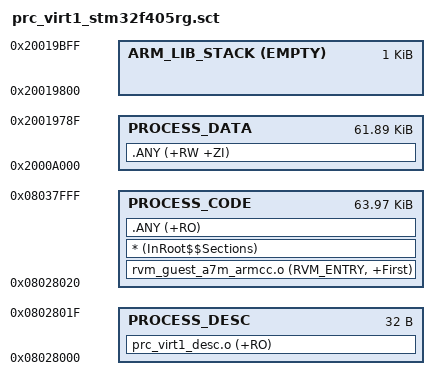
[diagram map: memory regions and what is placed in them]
;******************************************************************************
;Filename    : proc_virt1_stm32f405rg.sct
;Author      : The RVM project generator.
;Date        : 16/08/2024 22:18:27
;Licence     : Unlicense; see COPYING for details.
;Description : The scatter file for ARMv7-M layout. This file is intended
;              to be used with STM32F405RG.
;******************************************************************************

;Descriptor *******************************************************************
DESC 0x8028000 0x20
{
    ;Process header segment
    PROCESS_DESC 0x8028000 0x20
    {
        ;Process header
        prc_virt1_desc.o         (+RO)
    }
}
;End Descriptor ***************************************************************

;Process **********************************************************************
PROCESS 0x8028020 0xFFE0
{
    ;Process code segment
    PROCESS_CODE 0x8028020 0xFFE0
    {
        ;Entry point assembly
        rvm_guest_a7m_armcc.o     (RVM_ENTRY, +First)
        ;The lib code copying code
        *                      (InRoot$$Sections)
        ;The other code sections
        .ANY                   (+RO)
    }

    ;Process data segment
    PROCESS_DATA 0x2000A000 0xF790
    {
        .ANY                   (+RW +ZI)
    }

    ;Process stack segment - required by armlib; reusing the booting thread's
    ARM_LIB_STACK 0x20019800 EMPTY 0x400
    {

    }
}
;End Process ******************************************************************

;End Of File ******************************************************************

;Copyright (C) Evo-Devo Instrum. All rights reserved **************************

